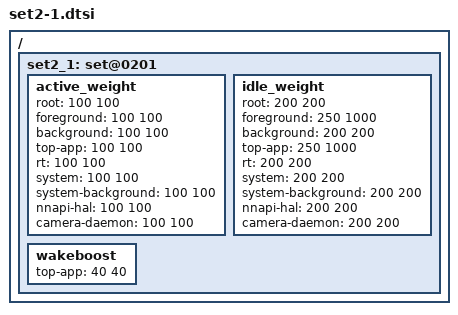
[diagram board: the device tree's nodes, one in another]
/ {
	/* performance mode - touch boost */
	set2_1: set@0201 {
		active_weight {
			root = <100 100>;
			foreground = <100 100>;
			background = <100 100>;
			top-app = <100 100>;
			rt = <100 100>;
			system = <100 100>;
			system-background = <100 100>;
			nnapi-hal = <100 100>;
			camera-daemon = <100 100>;
		};

		idle_weight {
			root = <200 200>;
			foreground = <250 1000>;
			background = <200 200>;
			top-app = <250 1000>;
			rt = <200 200>;
			system = <200 200>;
			system-background = <200 200>;
			nnapi-hal = <200 200>;
			camera-daemon = <200 200>;
		};

		wakeboost {
			top-app = <40 40>;
		};
	};
};
